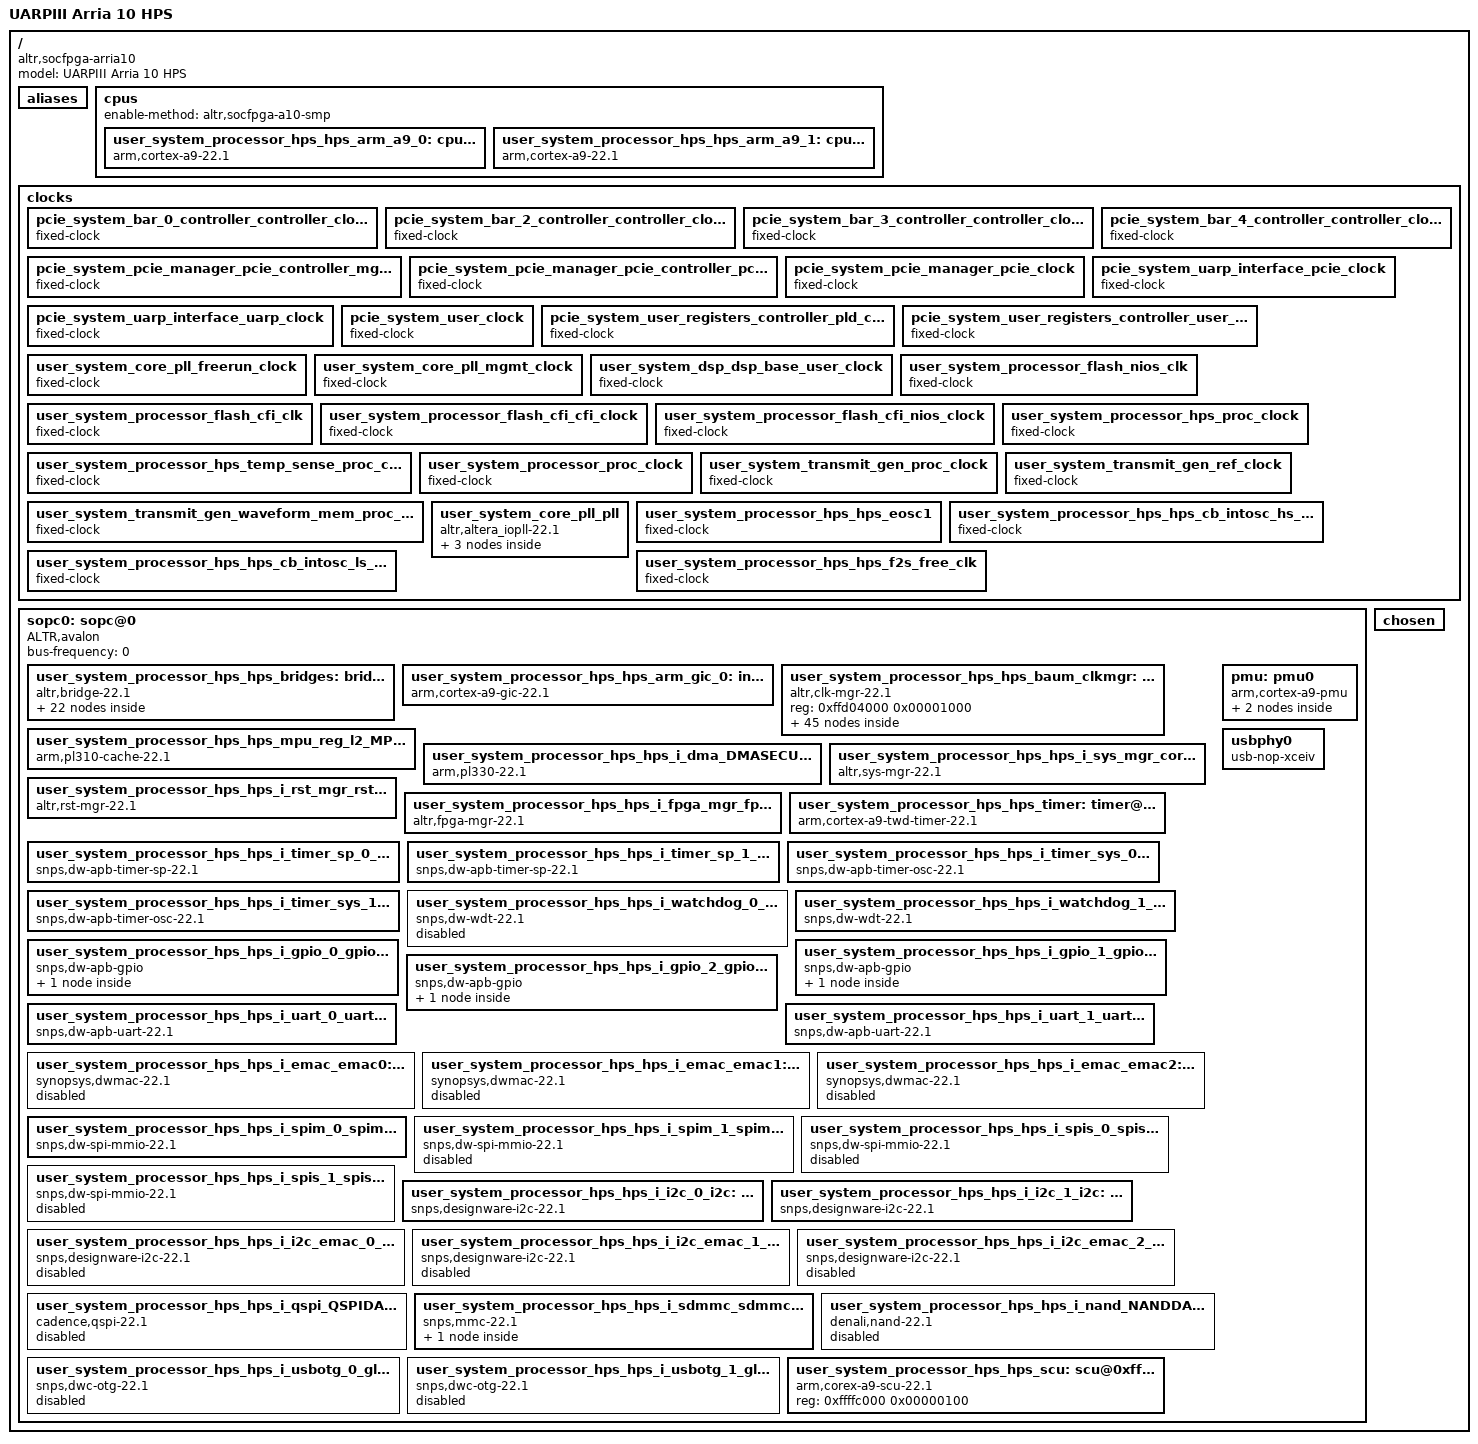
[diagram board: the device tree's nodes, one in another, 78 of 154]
/*
 * This devicetree is generated by sopc2dts version 20.1 [9b3346002ac555f36b80b1bc56dad1cb86298234] on Wed Jan 10 18:21:34 GMT 2024
 * Sopc2dts is written by Walter Goossens <waltergoossens@home.nl>
 * in cooperation with the nios2 community <nios2-dev@lists.rocketboards.org>
 */
/dts-v1/;

/ {
	model = "UARPIII Arria 10 HPS";	/* appended from boardinfo */
	compatible = "altr,socfpga-arria10", "altr,socfpga";	/* appended from boardinfo */
	#address-cells = <1>;
	#size-cells = <1>;

	aliases {
		serial0 = "/sopc@0/serial@0xffc02000";
		serial1 = "/sopc@0/serial@0xffc02100";
		watchdog0 = "/sopc@0/timer@0xffd00200";
		watchdog1 = "/sopc@0/timer@0xffd00300";
		bootargs = "console=ttyS0,115200";	/* appended from boardinfo */
	}; //end aliases

	cpus {
		#address-cells = <1>;
		#size-cells = <0>;
		enable-method = "altr,socfpga-a10-smp";	/* appended from boardinfo */

		user_system_processor_hps_hps_arm_a9_0: cpu@0x0 {
			device_type = "cpu";
			compatible = "arm,cortex-a9-22.1", "arm,cortex-a9";
			reg = <0x00000000>;
			next-level-cache = <&user_system_processor_hps_hps_mpu_reg_l2_MPUL2>;	/* appended from boardinfo */
		}; //end cpu@0x0 (user_system_processor_hps_hps_arm_a9_0)

		user_system_processor_hps_hps_arm_a9_1: cpu@0x1 {
			device_type = "cpu";
			compatible = "arm,cortex-a9-22.1", "arm,cortex-a9";
			reg = <0x00000001>;
			next-level-cache = <&user_system_processor_hps_hps_mpu_reg_l2_MPUL2>;	/* appended from boardinfo */
		}; //end cpu@0x1 (user_system_processor_hps_hps_arm_a9_1)
	}; //end cpus

	clocks {
		#address-cells = <1>;
		#size-cells = <1>;

		pcie_system_bar_0_controller_controller_clock: pcie_system_bar_0_controller_controller_clock {
			compatible = "fixed-clock";
			#clock-cells = <0>;
			clock-frequency = <250000000>;	/* 250.00 MHz */
			clock-output-names = "pcie_system_bar_0_controller_controller_clock-clk";
		}; //end pcie_system_bar_0_controller_controller_clock (pcie_system_bar_0_controller_controller_clock)

		pcie_system_bar_2_controller_controller_clock: pcie_system_bar_2_controller_controller_clock {
			compatible = "fixed-clock";
			#clock-cells = <0>;
			clock-frequency = <250000000>;	/* 250.00 MHz */
			clock-output-names = "pcie_system_bar_2_controller_controller_clock-clk";
		}; //end pcie_system_bar_2_controller_controller_clock (pcie_system_bar_2_controller_controller_clock)

		pcie_system_bar_3_controller_controller_clock: pcie_system_bar_3_controller_controller_clock {
			compatible = "fixed-clock";
			#clock-cells = <0>;
			clock-frequency = <250000000>;	/* 250.00 MHz */
			clock-output-names = "pcie_system_bar_3_controller_controller_clock-clk";
		}; //end pcie_system_bar_3_controller_controller_clock (pcie_system_bar_3_controller_controller_clock)

		pcie_system_bar_4_controller_controller_clock: pcie_system_bar_4_controller_controller_clock {
			compatible = "fixed-clock";
			#clock-cells = <0>;
			clock-frequency = <250000000>;	/* 250.00 MHz */
			clock-output-names = "pcie_system_bar_4_controller_controller_clock-clk";
		}; //end pcie_system_bar_4_controller_controller_clock (pcie_system_bar_4_controller_controller_clock)

		pcie_system_pcie_manager_pcie_controller_mgmt_clock: pcie_system_pcie_manager_pcie_controller_mgmt_clock {
			compatible = "fixed-clock";
			#clock-cells = <0>;
			clock-frequency = <0>;	/* 0.00 Hz */
			clock-output-names = "pcie_system_pcie_manager_pcie_controller_mgmt_clock-clk";
		}; //end pcie_system_pcie_manager_pcie_controller_mgmt_clock (pcie_system_pcie_manager_pcie_controller_mgmt_clock)

		pcie_system_pcie_manager_pcie_controller_pcie_clock: pcie_system_pcie_manager_pcie_controller_pcie_clock {
			compatible = "fixed-clock";
			#clock-cells = <0>;
			clock-frequency = <250000000>;	/* 250.00 MHz */
			clock-output-names = "pcie_system_pcie_manager_pcie_controller_pcie_clock-clk";
		}; //end pcie_system_pcie_manager_pcie_controller_pcie_clock (pcie_system_pcie_manager_pcie_controller_pcie_clock)

		pcie_system_pcie_manager_pcie_clock: pcie_system_pcie_manager_pcie_clock {
			compatible = "fixed-clock";
			#clock-cells = <0>;
			clock-frequency = <250000000>;	/* 250.00 MHz */
			clock-output-names = "pcie_system_pcie_manager_pcie_clock-clk";
		}; //end pcie_system_pcie_manager_pcie_clock (pcie_system_pcie_manager_pcie_clock)

		pcie_system_uarp_interface_pcie_clock: pcie_system_uarp_interface_pcie_clock {
			compatible = "fixed-clock";
			#clock-cells = <0>;
			clock-frequency = <250000000>;	/* 250.00 MHz */
			clock-output-names = "pcie_system_uarp_interface_pcie_clock-clk";
		}; //end pcie_system_uarp_interface_pcie_clock (pcie_system_uarp_interface_pcie_clock)

		pcie_system_uarp_interface_uarp_clock: pcie_system_uarp_interface_uarp_clock {
			compatible = "fixed-clock";
			#clock-cells = <0>;
			clock-frequency = <200000000>;	/* 200.00 MHz */
			clock-output-names = "pcie_system_uarp_interface_uarp_clock-clk";
		}; //end pcie_system_uarp_interface_uarp_clock (pcie_system_uarp_interface_uarp_clock)

		pcie_system_user_clock: pcie_system_user_clock {
			compatible = "fixed-clock";
			#clock-cells = <0>;
			clock-frequency = <200000000>;	/* 200.00 MHz */
			clock-output-names = "pcie_system_user_clock-clk";
		}; //end pcie_system_user_clock (pcie_system_user_clock)

		pcie_system_user_registers_controller_pld_clock: pcie_system_user_registers_controller_pld_clock {
			compatible = "fixed-clock";
			#clock-cells = <0>;
			clock-frequency = <250000000>;	/* 250.00 MHz */
			clock-output-names = "pcie_system_user_registers_controller_pld_clock-clk";
		}; //end pcie_system_user_registers_controller_pld_clock (pcie_system_user_registers_controller_pld_clock)

		pcie_system_user_registers_controller_user_clock: pcie_system_user_registers_controller_user_clock {
			compatible = "fixed-clock";
			#clock-cells = <0>;
			clock-frequency = <200000000>;	/* 200.00 MHz */
			clock-output-names = "pcie_system_user_registers_controller_user_clock-clk";
		}; //end pcie_system_user_registers_controller_user_clock (pcie_system_user_registers_controller_user_clock)

		user_system_core_pll_freerun_clock: user_system_core_pll_freerun_clock {
			compatible = "fixed-clock";
			#clock-cells = <0>;
			clock-frequency = <100000000>;	/* 100.00 MHz */
			clock-output-names = "user_system_core_pll_freerun_clock-clk";
		}; //end user_system_core_pll_freerun_clock (user_system_core_pll_freerun_clock)

		user_system_core_pll_mgmt_clock: user_system_core_pll_mgmt_clock {
			compatible = "fixed-clock";
			#clock-cells = <0>;
			clock-frequency = <100000000>;	/* 100.00 MHz */
			clock-output-names = "user_system_core_pll_mgmt_clock-clk";
		}; //end user_system_core_pll_mgmt_clock (user_system_core_pll_mgmt_clock)

		user_system_dsp_dsp_base_user_clock: user_system_dsp_dsp_base_user_clock {
			compatible = "fixed-clock";
			#clock-cells = <0>;
			clock-frequency = <200000000>;	/* 200.00 MHz */
			clock-output-names = "user_system_dsp_dsp_base_user_clock-clk";
		}; //end user_system_dsp_dsp_base_user_clock (user_system_dsp_dsp_base_user_clock)

		user_system_processor_flash_nios_clk: user_system_processor_flash_nios_clk {
			compatible = "fixed-clock";
			#clock-cells = <0>;
			clock-frequency = <200000000>;	/* 200.00 MHz */
			clock-output-names = "user_system_processor_flash_nios_clk-clk";
		}; //end user_system_processor_flash_nios_clk (user_system_processor_flash_nios_clk)

		user_system_processor_flash_cfi_clk: user_system_processor_flash_cfi_clk {
			compatible = "fixed-clock";
			#clock-cells = <0>;
			clock-frequency = <2500000>;	/* 2.50 MHz */
			clock-output-names = "user_system_processor_flash_cfi_clk-clk";
		}; //end user_system_processor_flash_cfi_clk (user_system_processor_flash_cfi_clk)

		user_system_processor_flash_cfi_cfi_clock: user_system_processor_flash_cfi_cfi_clock {
			compatible = "fixed-clock";
			#clock-cells = <0>;
			clock-frequency = <2500000>;	/* 2.50 MHz */
			clock-output-names = "user_system_processor_flash_cfi_cfi_clock-clk";
		}; //end user_system_processor_flash_cfi_cfi_clock (user_system_processor_flash_cfi_cfi_clock)

		user_system_processor_flash_cfi_nios_clock: user_system_processor_flash_cfi_nios_clock {
			compatible = "fixed-clock";
			#clock-cells = <0>;
			clock-frequency = <200000000>;	/* 200.00 MHz */
			clock-output-names = "user_system_processor_flash_cfi_nios_clock-clk";
		}; //end user_system_processor_flash_cfi_nios_clock (user_system_processor_flash_cfi_nios_clock)

		user_system_processor_hps_proc_clock: user_system_processor_hps_proc_clock {
			compatible = "fixed-clock";
			#clock-cells = <0>;
			clock-frequency = <200000000>;	/* 200.00 MHz */
			clock-output-names = "user_system_processor_hps_proc_clock-clk";
		}; //end user_system_processor_hps_proc_clock (user_system_processor_hps_proc_clock)

		user_system_processor_hps_temp_sense_proc_clock: user_system_processor_hps_temp_sense_proc_clock {
			compatible = "fixed-clock";
			#clock-cells = <0>;
			clock-frequency = <200000000>;	/* 200.00 MHz */
			clock-output-names = "user_system_processor_hps_temp_sense_proc_clock-clk";
		}; //end user_system_processor_hps_temp_sense_proc_clock (user_system_processor_hps_temp_sense_proc_clock)

		user_system_processor_proc_clock: user_system_processor_proc_clock {
			compatible = "fixed-clock";
			#clock-cells = <0>;
			clock-frequency = <200000000>;	/* 200.00 MHz */
			clock-output-names = "user_system_processor_proc_clock-clk";
		}; //end user_system_processor_proc_clock (user_system_processor_proc_clock)

		user_system_transmit_gen_proc_clock: user_system_transmit_gen_proc_clock {
			compatible = "fixed-clock";
			#clock-cells = <0>;
			clock-frequency = <200000000>;	/* 200.00 MHz */
			clock-output-names = "user_system_transmit_gen_proc_clock-clk";
		}; //end user_system_transmit_gen_proc_clock (user_system_transmit_gen_proc_clock)

		user_system_transmit_gen_ref_clock: user_system_transmit_gen_ref_clock {
			compatible = "fixed-clock";
			#clock-cells = <0>;
			clock-frequency = <20000000>;	/* 20.00 MHz */
			clock-output-names = "user_system_transmit_gen_ref_clock-clk";
		}; //end user_system_transmit_gen_ref_clock (user_system_transmit_gen_ref_clock)

		user_system_transmit_gen_waveform_mem_proc_clock: user_system_transmit_gen_waveform_mem_proc_clock {
			compatible = "fixed-clock";
			#clock-cells = <0>;
			clock-frequency = <200000000>;	/* 200.00 MHz */
			clock-output-names = "user_system_transmit_gen_waveform_mem_proc_clock-clk";
		}; //end user_system_transmit_gen_waveform_mem_proc_clock (user_system_transmit_gen_waveform_mem_proc_clock)

		user_system_core_pll_pll: user_system_core_pll_pll {
			compatible = "altr,altera_iopll-22.1";
			#clock-cells = <1>;

			user_system_core_pll_pll_outclk0: user_system_core_pll_pll_outclk0 {
				compatible = "fixed-clock";
				#clock-cells = <0>;
				clock-frequency = <20000000>;	/* 20.00 MHz */
				clock-output-names = "user_system_core_pll_pll-outclk0";
			}; //end user_system_core_pll_pll_outclk0 (user_system_core_pll_pll_outclk0)

			user_system_core_pll_pll_outclk1: user_system_core_pll_pll_outclk1 {
				compatible = "fixed-clock";
				#clock-cells = <0>;
				clock-frequency = <120000000>;	/* 120.00 MHz */
				clock-output-names = "user_system_core_pll_pll-outclk1";
			}; //end user_system_core_pll_pll_outclk1 (user_system_core_pll_pll_outclk1)

			user_system_core_pll_pll_outclk2: user_system_core_pll_pll_outclk2 {
				compatible = "fixed-clock";
				#clock-cells = <0>;
				clock-frequency = <240000000>;	/* 240.00 MHz */
				clock-output-names = "user_system_core_pll_pll-outclk2";
			}; //end user_system_core_pll_pll_outclk2 (user_system_core_pll_pll_outclk2)
		}; //end user_system_core_pll_pll (user_system_core_pll_pll)

		user_system_processor_hps_hps_eosc1: user_system_processor_hps_hps_eosc1 {
			compatible = "fixed-clock";
			#clock-cells = <0>;
			clock-frequency = <25000000>;	/* 25.00 MHz */
			clock-output-names = "user_system_processor_hps_hps_eosc1-clk";
		}; //end user_system_processor_hps_hps_eosc1 (user_system_processor_hps_hps_eosc1)

		user_system_processor_hps_hps_cb_intosc_hs_div2_clk: user_system_processor_hps_hps_cb_intosc_hs_div2_clk {
			compatible = "fixed-clock";
			#clock-cells = <0>;
			clock-frequency = <0>;	/* 0.00 Hz */
			clock-output-names = "user_system_processor_hps_hps_cb_intosc_hs_div2_clk-clk";
		}; //end user_system_processor_hps_hps_cb_intosc_hs_div2_clk (user_system_processor_hps_hps_cb_intosc_hs_div2_clk)

		user_system_processor_hps_hps_cb_intosc_ls_clk: user_system_processor_hps_hps_cb_intosc_ls_clk {
			compatible = "fixed-clock";
			#clock-cells = <0>;
			clock-frequency = <60000000>;	/* 60.00 MHz */
			clock-output-names = "user_system_processor_hps_hps_cb_intosc_ls_clk-clk";
		}; //end user_system_processor_hps_hps_cb_intosc_ls_clk (user_system_processor_hps_hps_cb_intosc_ls_clk)

		user_system_processor_hps_hps_f2s_free_clk: user_system_processor_hps_hps_f2s_free_clk {
			compatible = "fixed-clock";
			#clock-cells = <0>;
			clock-frequency = <200000000>;	/* 200.00 MHz */
			clock-output-names = "user_system_processor_hps_hps_f2s_free_clk-clk";
		}; //end user_system_processor_hps_hps_f2s_free_clk (user_system_processor_hps_hps_f2s_free_clk)
	}; //end clocks

	sopc0: sopc@0 {
		device_type = "soc";
		ranges;
		#address-cells = <1>;
		#size-cells = <1>;
		compatible = "ALTR,avalon", "simple-bus";
		bus-frequency = <0>;

		user_system_processor_hps_hps_bridges: bridge@0xc0000000 {
			compatible = "altr,bridge-22.1", "simple-bus";
			reg = <0xc0000000 0x20000000>,
				<0xff200000 0x00200000>;
			reg-names = "axi_h2f", "axi_h2f_lw";
			clocks = <&user_system_processor_hps_proc_clock &user_system_processor_hps_proc_clock>;
			clock-names = "h2f_axi_clock", "h2f_lw_axi_clock";
			#address-cells = <2>;
			#size-cells = <1>;
			ranges = <0x00000000 0x2e000000 0xee000000 0x00002000>,
				<0x00000000 0x2f000000 0xef000000 0x00010000>,
				<0x00000000 0x30000000 0xf0000000 0x00000040>,
				<0x00000000 0x34000000 0xf4000000 0x04000000>,
				<0x00000001 0x001c0000 0xff3c0000 0x00000008>,
				<0x00000001 0x001c4000 0xff3c4000 0x00000020>,
				<0x00000001 0x001c4400 0xff3c4400 0x00000020>,
				<0x00000001 0x001c4800 0xff3c4800 0x00000020>,
				<0x00000001 0x001c8000 0xff3c8000 0x00000004>,
				<0x00000001 0x00010000 0xff210000 0x00000020>,
				<0x00000001 0x00000000 0xff200000 0x00000020>,
				<0x00000001 0x00008000 0xff208000 0x00000010>,
				<0x00000001 0x00004000 0xff204000 0x00000040>,
				<0x00000001 0x00114000 0xff314000 0x00000010>,
				<0x00000001 0x00104010 0xff304010 0x00000010>,
				<0x00000001 0x00104000 0xff304000 0x00000010>,
				<0x00000001 0x00108000 0xff308000 0x00000400>,
				<0x00000001 0x0010c000 0xff30c000 0x00001000>,
				<0x00000001 0x00140000 0xff340000 0x00040000>,
				<0x00000001 0x00100000 0xff300000 0x00000010>,
				<0x00000001 0x0012c000 0xff32c000 0x00000800>,
				<0x00000001 0x0012c800 0xff32c800 0x00000010>,
				<0x00000001 0x0012d000 0xff32d000 0x00000004>;

			user_system_processor_pcie_read_mem: unknown@0x02e000000 {
				compatible = "unknown,unknown-1.0";
				reg = <0x00000000 0x2e000000 0x00002000>;
				clocks = <&user_system_processor_proc_clock>;
			}; //end unknown@0x02e000000 (user_system_processor_pcie_read_mem)

			user_system_processor_pcie_write_width: unknown@0x02f000000 {
				compatible = "unknown,unknown-1.0";
				reg = <0x00000000 0x2f000000 0x00010000>;
				clocks = <&user_system_processor_proc_clock>;
			}; //end unknown@0x02f000000 (user_system_processor_pcie_write_width)

			user_system_processor_flash_cfi_mac: quadspi@0x030000000 {
				compatible = "altr,quadspi-22.1", "altr,quadspi-2.0";
				reg = <0x00000000 0x30000000 0x00000040>,
					<0x00000000 0x34000000 0x04000000>;
				reg-names = "avl_csr", "avl_mem";
				clocks = <&user_system_processor_flash_cfi_cfi_clock>;
			}; //end quadspi@0x030000000 (user_system_processor_flash_cfi_mac)

			user_system_processor_hps_hps_sysid: sysid@0x1001c0000 {
				compatible = "altr,sysid-22.1", "altr,sysid-1.0";
				reg = <0x00000001 0x001c0000 0x00000008>;
				clocks = <&user_system_processor_hps_proc_clock>;
				id = <1887048173>;	/* embeddedsw.dts.params.id type NUMBER */
				timestamp = <1704296836>;	/* embeddedsw.dts.params.timestamp type NUMBER */
			}; //end sysid@0x1001c0000 (user_system_processor_hps_hps_sysid)

			user_system_processor_hps_crc16_processor: unknown@0x1001c4000 {
				compatible = "unknown,unknown-1.0";
				reg = <0x00000001 0x001c4000 0x00000020>;
				clocks = <&user_system_processor_hps_proc_clock>;
			}; //end unknown@0x1001c4000 (user_system_processor_hps_crc16_processor)

			user_system_processor_hps_crc32_processor: unknown@0x1001c4400 {
				compatible = "unknown,unknown-1.0";
				reg = <0x00000001 0x001c4400 0x00000020>;
				clocks = <&user_system_processor_hps_proc_clock>;
			}; //end unknown@0x1001c4400 (user_system_processor_hps_crc32_processor)

			user_system_processor_hps_mosys_ecc19: unknown@0x1001c4800 {
				compatible = "unknown,unknown-1.0";
				reg = <0x00000001 0x001c4800 0x00000020>;
				clocks = <&user_system_processor_hps_proc_clock>;
			}; //end unknown@0x1001c4800 (user_system_processor_hps_mosys_ecc19)

			user_system_processor_hps_temp_sense_tsd_controller: unknown@0x1001c8000 {
				compatible = "unknown,unknown-1.0";
				reg = <0x00000001 0x001c8000 0x00000004>;
				clocks = <&user_system_processor_hps_temp_sense_proc_clock>;
			}; //end unknown@0x1001c8000 (user_system_processor_hps_temp_sense_tsd_controller)

			user_system_global_csr: unknown@0x100010000 {
				compatible = "unknown,unknown-1.0";
				reg = <0x00000001 0x00010000 0x00000020>;
				interrupt-parent = <&user_system_processor_hps_hps_arm_gic_0>;
				interrupts = <0 24 4>;
			}; //end unknown@0x100010000 (user_system_global_csr)

			user_system_dsp_dsp_base_dma_read_controller: unknown@0x100000000 {
				compatible = "unknown,unknown-1.0";
				reg = <0x00000001 0x00000000 0x00000020>;
				interrupt-parent = <&user_system_processor_hps_hps_arm_gic_0>;
				interrupts = <0 23 4>;
				clocks = <&user_system_dsp_dsp_base_user_clock>;
			}; //end unknown@0x100000000 (user_system_dsp_dsp_base_dma_read_controller)

			user_system_dsp_sample_processor: unknown@0x100008000 {
				compatible = "unknown,unknown-1.0";
				reg = <0x00000001 0x00008000 0x00000010>;
				interrupt-parent = <&user_system_processor_hps_hps_arm_gic_0>;
				interrupts = <0 25 4>;
				interrupt-controller;
				#interrupt-cells = <1>;
			}; //end unknown@0x100008000 (user_system_dsp_sample_processor)

			user_system_dsp_dsp_base_processing_csr_null: unknown@0x100004000 {
				compatible = "unknown,unknown-1.0";
				reg = <0x00000001 0x00004000 0x00000040>;
				clocks = <&user_system_dsp_dsp_base_user_clock>;
			}; //end unknown@0x100004000 (user_system_dsp_dsp_base_processing_csr_null)

			user_system_processor_modbus: unknown@0x100114000 {
				compatible = "unknown,unknown-1.0";
				reg = <0x00000001 0x00114000 0x00000010>;
				interrupt-parent = <&user_system_processor_hps_hps_arm_gic_0>;
				interrupts = <0 51 4>;
				clocks = <&user_system_processor_proc_clock>;
			}; //end unknown@0x100114000 (user_system_processor_modbus)

			user_system_processor_high_queue: unknown@0x100104010 {
				compatible = "unknown,unknown-1.0";
				reg = <0x00000001 0x00104010 0x00000010>;
				clocks = <&user_system_processor_proc_clock>;
			}; //end unknown@0x100104010 (user_system_processor_high_queue)

			user_system_processor_low_queue: unknown@0x100104000 {
				compatible = "unknown,unknown-1.0";
				reg = <0x00000001 0x00104000 0x00000010>;
				clocks = <&user_system_processor_proc_clock>;
			}; //end unknown@0x100104000 (user_system_processor_low_queue)

			user_system_processor_tlp_dma: unknown@0x100108000 {
				compatible = "unknown,unknown-1.0";
				reg = <0x00000001 0x00108000 0x00000400>;
				clocks = <&user_system_processor_proc_clock>;
			}; //end unknown@0x100108000 (user_system_processor_tlp_dma)

			user_system_processor_pcie_config_mem: unknown@0x10010c000 {
				compatible = "unknown,unknown-1.0";
				reg = <0x00000001 0x0010c000 0x00001000>;
				clocks = <&user_system_processor_proc_clock>;
			}; //end unknown@0x10010c000 (user_system_processor_pcie_config_mem)

			user_system_processor_sample_map: unknown@0x100140000 {
				compatible = "unknown,unknown-1.0";
				reg = <0x00000001 0x00140000 0x00040000>;
				clocks = <&user_system_processor_proc_clock>;
			}; //end unknown@0x100140000 (user_system_processor_sample_map)

			user_system_processor_flash_cfi_watchdog_fpga: gpio@0x100100000 {
				compatible = "altr,pio-22.1", "altr,pio-1.0";
				reg = <0x00000001 0x00100000 0x00000010>;
				clocks = <&user_system_processor_flash_cfi_nios_clock>;
				altr,gpio-bank-width = <1>;	/* embeddedsw.dts.params.altr,gpio-bank-width type NUMBER */
				resetvalue = <0>;	/* embeddedsw.dts.params.resetvalue type NUMBER */
				#gpio-cells = <2>;
				gpio-controller;
			}; //end gpio@0x100100000 (user_system_processor_flash_cfi_watchdog_fpga)

			user_system_core_pll_pll_reconfig: unknown@0x10012c000 {
				compatible = "unknown,unknown-22.1";
				reg = <0x00000001 0x0012c000 0x00000800>;
				clocks = <&user_system_core_pll_mgmt_clock>;
			}; //end unknown@0x10012c000 (user_system_core_pll_pll_reconfig)

			user_system_core_pll_pll_reconfig_pio: gpio@0x10012c800 {
				compatible = "altr,pio-1.0", "altr,pio-1.0";
				reg = <0x00000001 0x0012c800 0x00000010>;
				clocks = <&user_system_core_pll_mgmt_clock>;
				altr,gpio-bank-width = <2>;	/* embeddedsw.dts.params.altr,gpio-bank-width type NUMBER */
				resetvalue = <0>;	/* embeddedsw.dts.params.resetvalue type NUMBER */
				#gpio-cells = <2>;
				gpio-controller;
			}; //end gpio@0x10012c800 (user_system_core_pll_pll_reconfig_pio)

			user_system_core_pll_trig_clk_sel: unknown@0x10012d000 {
				compatible = "unknown,unknown-1.0";
				reg = <0x00000001 0x0012d000 0x00000004>;
				clocks = <&user_system_core_pll_mgmt_clock>;
			}; //end unknown@0x10012d000 (user_system_core_pll_trig_clk_sel)
		}; //end bridge@0xc0000000 (user_system_processor_hps_hps_bridges)

		user_system_processor_hps_hps_arm_gic_0: intc@0xffffd000 {
			compatible = "arm,cortex-a9-gic-22.1", "arm,cortex-a9-gic";
			reg = <0xffffd000 0x00001000>,
				<0xffffc100 0x00000100>;
			reg-names = "axi_slave0", "axi_slave1";
			interrupt-controller;
			#interrupt-cells = <3>;
		}; //end intc@0xffffd000 (user_system_processor_hps_hps_arm_gic_0)

		user_system_processor_hps_hps_baum_clkmgr: clkmgr@0xffd04000 {
			compatible = "altr,clk-mgr-22.1", "altr,clk-mgr";
			reg = <0xffd04000 0x00001000>;
			clock-names = "eosc1", "cb_intosc_hs_div2_clk", "cb_intosc_ls_clk", "f2s_free_clk";

			clocks {
				#size-cells = <0>;
				#address-cells = <1>;

				main_pll: main_pll {
					compatible = "altr,socfpga-a10-pll-clock";
					reg = <0x00000040>;
					clocks = <&user_system_processor_hps_hps_eosc1 &user_system_processor_hps_hps_cb_intosc_ls_clk &user_system_processor_hps_hps_f2s_free_clk>;
					clock-names = "user_system_processor_hps_hps_eosc1", "user_system_processor_hps_hps_cb_intosc_ls_clk", "user_system_processor_hps_hps_f2s_free_clk";
					#clock-cells = <0>;
					#address-cells = <1>;
					#size-cells = <0>;

					main_mpu_base_clk: main_mpu_base_clk {
						compatible = "altr,socfpga-a10-perip-clk";
						clocks = <&main_pll>;
						#clock-cells = <0>;
						div-reg = <0x00000140 0x00000000 0x0000000b>;
					}; //end main_mpu_base_clk (main_mpu_base_clk)

					main_noc_base_clk: main_noc_base_clk {
						compatible = "altr,socfpga-a10-perip-clk";
						clocks = <&main_pll>;
						#clock-cells = <0>;
						div-reg = <0x00000144 0x00000000 0x0000000b>;
					}; //end main_noc_base_clk (main_noc_base_clk)

					main_emaca_clk: main_emaca_clk {
						compatible = "altr,socfpga-a10-perip-clk";
						reg = <0x00000068>;
						clocks = <&main_pll>;
						#clock-cells = <0>;
					}; //end main_emaca_clk (main_emaca_clk)

					main_emacb_clk: main_emacb_clk {
						compatible = "altr,socfpga-a10-perip-clk";
						reg = <0x0000006c>;
						clocks = <&main_pll>;
						#clock-cells = <0>;
					}; //end main_emacb_clk (main_emacb_clk)

					main_emac_ptp_clk: main_emac_ptp_clk {
						compatible = "altr,socfpga-a10-perip-clk";
						reg = <0x00000070>;
						clocks = <&main_pll>;
						#clock-cells = <0>;
					}; //end main_emac_ptp_clk (main_emac_ptp_clk)

					main_gpio_db_clk: main_gpio_db_clk {
						compatible = "altr,socfpga-a10-perip-clk";
						reg = <0x00000074>;
						clocks = <&main_pll>;
						#clock-cells = <0>;
					}; //end main_gpio_db_clk (main_gpio_db_clk)

					main_sdmmc_clk: main_sdmmc_clk {
						compatible = "altr,socfpga-a10-perip-clk";
						reg = <0x00000078>;
						clocks = <&main_pll>;
						#clock-cells = <0>;
					}; //end main_sdmmc_clk (main_sdmmc_clk)

					main_s2f_usr0_clk: main_s2f_usr0_clk {
						compatible = "altr,socfpga-a10-perip-clk";
						reg = <0x0000007c>;
						clocks = <&main_pll>;
						#clock-cells = <0>;
					}; //end main_s2f_usr0_clk (main_s2f_usr0_clk)

					main_s2f_usr1_clk: main_s2f_usr1_clk {
						compatible = "altr,socfpga-a10-perip-clk";
						reg = <0x00000080>;
						clocks = <&main_pll>;
						#clock-cells = <0>;
					}; //end main_s2f_usr1_clk (main_s2f_usr1_clk)

					main_hmc_pll_ref_clk: main_hmc_pll_ref_clk {
						compatible = "altr,socfpga-a10-perip-clk";
						reg = <0x00000084>;
						clocks = <&main_pll>;
						#clock-cells = <0>;
					}; //end main_hmc_pll_ref_clk (main_hmc_pll_ref_clk)

					main_periph_ref_clk: main_periph_ref_clk {
						compatible = "altr,socfpga-a10-perip-clk";
						reg = <0x0000009c>;
						clocks = <&main_pll>;
						#clock-cells = <0>;
					}; //end main_periph_ref_clk (main_periph_ref_clk)
				}; //end main_pll (main_pll)

				periph_pll: periph_pll {
					compatible = "altr,socfpga-a10-pll-clock";
					reg = <0x000000c0>;
					clocks = <&user_system_processor_hps_hps_eosc1 &user_system_processor_hps_hps_cb_intosc_ls_clk &user_system_processor_hps_hps_f2s_free_clk &main_periph_ref_clk>;
					clock-names = "user_system_processor_hps_hps_eosc1", "user_system_processor_hps_hps_cb_intosc_ls_clk", "user_system_processor_hps_hps_f2s_free_clk", "main_periph_ref_clk";
					#clock-cells = <0>;
					#address-cells = <1>;
					#size-cells = <0>;

					peri_mpu_base_clk: peri_mpu_base_clk {
						compatible = "altr,socfpga-a10-perip-clk";
						clocks = <&periph_pll>;
						#clock-cells = <0>;
						div-reg = <0x00000140 0x00000010 0x0000000b>;
					}; //end peri_mpu_base_clk (peri_mpu_base_clk)

					peri_noc_base_clk: peri_noc_base_clk {
						compatible = "altr,socfpga-a10-perip-clk";
						clocks = <&periph_pll>;
						#clock-cells = <0>;
						div-reg = <0x00000144 0x00000010 0x0000000b>;
					}; //end peri_noc_base_clk (peri_noc_base_clk)

					peri_emaca_clk: peri_emaca_clk {
						compatible = "altr,socfpga-a10-perip-clk";
						reg = <0x000000e8>;
						clocks = <&periph_pll>;
						#clock-cells = <0>;
					}; //end peri_emaca_clk (peri_emaca_clk)

					peri_emacb_clk: peri_emacb_clk {
						compatible = "altr,socfpga-a10-perip-clk";
						reg = <0x000000ec>;
						clocks = <&periph_pll>;
						#clock-cells = <0>;
					}; //end peri_emacb_clk (peri_emacb_clk)

					peri_emac_ptp_clk: peri_emac_ptp_clk {
						compatible = "altr,socfpga-a10-perip-clk";
						reg = <0x000000f0>;
						clocks = <&periph_pll>;
						#clock-cells = <0>;
					}; //end peri_emac_ptp_clk (peri_emac_ptp_clk)

					peri_gpio_db_clk: peri_gpio_db_clk {
						compatible = "altr,socfpga-a10-perip-clk";
						reg = <0x000000f4>;
						clocks = <&periph_pll>;
						#clock-cells = <0>;
					}; //end peri_gpio_db_clk (peri_gpio_db_clk)

					peri_sdmmc_clk: peri_sdmmc_clk {
						compatible = "altr,socfpga-a10-perip-clk";
						reg = <0x000000f8>;
						clocks = <&periph_pll>;
						#clock-cells = <0>;
					}; //end peri_sdmmc_clk (peri_sdmmc_clk)

					peri_s2f_usr0_clk: peri_s2f_usr0_clk {
						compatible = "altr,socfpga-a10-perip-clk";
						reg = <0x000000fc>;
						clocks = <&periph_pll>;
						#clock-cells = <0>;
					}; //end peri_s2f_usr0_clk (peri_s2f_usr0_clk)

					peri_s2f_usr1_clk: peri_s2f_usr1_clk {
						compatible = "altr,socfpga-a10-perip-clk";
						reg = <0x00000100>;
						clocks = <&periph_pll>;
						#clock-cells = <0>;
					}; //end peri_s2f_usr1_clk (peri_s2f_usr1_clk)

					peri_hmc_pll_ref_clk: peri_hmc_pll_ref_clk {
						compatible = "altr,socfpga-a10-perip-clk";
						reg = <0x00000104>;
						clocks = <&periph_pll>;
						#clock-cells = <0>;
					}; //end peri_hmc_pll_ref_clk (peri_hmc_pll_ref_clk)
				}; //end periph_pll (periph_pll)

				mpu_periph_clk: mpu_periph_clk {
					compatible = "altr,socfpga-a10-gate-clk";
					clocks = <&mpu_free_clk>;
					#clock-cells = <0>;
					clk-gate = <0x00000048 0x00000000>;
					fixed-divider = <4>;
				}; //end mpu_periph_clk (mpu_periph_clk)

				l4_main_clk: l4_main_clk {
					compatible = "altr,socfpga-a10-gate-clk";
					clocks = <&noc_free_clk>;
					#clock-cells = <0>;
					clk-gate = <0x00000048 0x00000001>;
					div-reg = <0x000000a8 0x00000000 0x00000002>;
				}; //end l4_main_clk (l4_main_clk)

				l4_mp_clk: l4_mp_clk {
					compatible = "altr,socfpga-a10-gate-clk";
					clocks = <&noc_free_clk>;
					#clock-cells = <0>;
					clk-gate = <0x00000048 0x00000002>;
					div-reg = <0x000000a8 0x00000008 0x00000002>;
				}; //end l4_mp_clk (l4_mp_clk)

				l4_sp_clk: l4_sp_clk {
					compatible = "altr,socfpga-a10-gate-clk";
					clocks = <&noc_free_clk>;
					#clock-cells = <0>;
					clk-gate = <0x00000048 0x00000003>;
					div-reg = <0x000000a8 0x00000010 0x00000002>;
				}; //end l4_sp_clk (l4_sp_clk)

				emac0_clk: emac0_clk {
					compatible = "altr,socfpga-a10-gate-clk";
					#clock-cells = <0>;
					clk-gate = <0x000000c8 0x00000000>;
				}; //end emac0_clk (emac0_clk)

				emac1_clk: emac1_clk {
					compatible = "altr,socfpga-a10-gate-clk";
					#clock-cells = <0>;
					clk-gate = <0x000000c8 0x00000001>;
				}; //end emac1_clk (emac1_clk)

				emac2_clk: emac2_clk {
					compatible = "altr,socfpga-a10-gate-clk";
					#clock-cells = <0>;
					clk-gate = <0x000000c8 0x00000002>;
				}; //end emac2_clk (emac2_clk)

				emac_ptp_clk: emac_ptp_clk {
					compatible = "altr,socfpga-a10-gate-clk";
					#clock-cells = <0>;
					clk-gate = <0x000000c8 0x00000003>;
				}; //end emac_ptp_clk (emac_ptp_clk)

				gpio_db_clk: gpio_db_clk {
					compatible = "altr,socfpga-a10-gate-clk";
					#clock-cells = <0>;
					clk-gate = <0x000000c8 0x00000004>;
				}; //end gpio_db_clk (gpio_db_clk)

				sdmmc_clk: sdmmc_clk {
					compatible = "altr,socfpga-a10-gate-clk";
					clocks = <&sdmmc_free_clk>;
					#clock-cells = <0>;
					clk-gate = <0x000000c8 0x00000005>;
					clk-phase = <0 135>;	/* appended from boardinfo */
				}; //end sdmmc_clk (sdmmc_clk)

				s2f_user1_clk: s2f_user1_clk {
					compatible = "altr,socfpga-a10-gate-clk";
					clocks = <&peri_s2f_usr1_clk>;
					#clock-cells = <0>;
					clk-gate = <0x000000c8 0x00000006>;
				}; //end s2f_user1_clk (s2f_user1_clk)

				reserved: reserved {
					compatible = "altr,socfpga-a10-gate-clk";
					#clock-cells = <0>;
					clk-gate = <0x000000c8 0x00000007>;
				}; //end reserved (reserved)

				usb_clk: usb_clk {
					compatible = "altr,socfpga-a10-gate-clk";
					clocks = <&l4_mp_clk>;
					#clock-cells = <0>;
					clk-gate = <0x000000c8 0x00000008>;
				}; //end usb_clk (usb_clk)

				spi_m_clk: spi_m_clk {
					compatible = "altr,socfpga-a10-gate-clk";
					clocks = <&l4_main_clk>;
					#clock-cells = <0>;
					clk-gate = <0x000000c8 0x00000009>;
				}; //end spi_m_clk (spi_m_clk)

				nand_clk: nand_clk {
					compatible = "altr,socfpga-a10-gate-clk";
					clocks = <&l4_mp_clk>;
					#clock-cells = <0>;
					clk-gate = <0x000000c8 0x0000000a>;
				}; //end nand_clk (nand_clk)

				qspi_clk: qspi_clk {
					compatible = "altr,socfpga-a10-gate-clk";
					clocks = <&l4_main_clk>;
					#clock-cells = <0>;
					clk-gate = <0x000000c8 0x0000000b>;
				}; //end qspi_clk (qspi_clk)

				mpu_free_clk: mpu_free_clk {
					compatible = "altr,socfpga-a10-perip-clk";
					clocks = <&main_mpu_base_clk &peri_mpu_base_clk &user_system_processor_hps_hps_eosc1 &user_system_processor_hps_hps_cb_intosc_hs_div2_clk &user_system_processor_hps_hps_f2s_free_clk>;
					clock-names = "main_mpu_base_clk", "peri_mpu_base_clk", "user_system_processor_hps_hps_eosc1", "user_system_processor_hps_hps_cb_intosc_hs_div2_clk", "user_system_processor_hps_hps_f2s_free_clk";
					#clock-cells = <0>;
					reg = <0x00000060>;
				}; //end mpu_free_clk (mpu_free_clk)

				noc_free_clk: noc_free_clk {
					compatible = "altr,socfpga-a10-perip-clk";
					clocks = <&main_noc_base_clk &peri_noc_base_clk &user_system_processor_hps_hps_eosc1 &user_system_processor_hps_hps_cb_intosc_hs_div2_clk &user_system_processor_hps_hps_f2s_free_clk>;
					clock-names = "main_noc_base_clk", "peri_noc_base_clk", "user_system_processor_hps_hps_eosc1", "user_system_processor_hps_hps_cb_intosc_hs_div2_clk", "user_system_processor_hps_hps_f2s_free_clk";
					#clock-cells = <0>;
					reg = <0x00000064>;
				}; //end noc_free_clk (noc_free_clk)

				s2f_usr1_clk: s2f_usr1_clk {
					compatible = "altr,socfpga-a10-perip-clk";
					clocks = <&main_s2f_usr1_clk &peri_s2f_usr1_clk &user_system_processor_hps_hps_eosc1 &user_system_processor_hps_hps_cb_intosc_hs_div2_clk &user_system_processor_hps_hps_f2s_free_clk>;
					clock-names = "main_s2f_usr1_clk", "peri_s2f_usr1_clk", "user_system_processor_hps_hps_eosc1", "user_system_processor_hps_hps_cb_intosc_hs_div2_clk", "user_system_processor_hps_hps_f2s_free_clk";
					#clock-cells = <0>;
					reg = <0x00000104>;
				}; //end s2f_usr1_clk (s2f_usr1_clk)

				sdmmc_free_clk: sdmmc_free_clk {
					compatible = "altr,socfpga-a10-perip-clk";
					clocks = <&main_sdmmc_clk &peri_sdmmc_clk &user_system_processor_hps_hps_eosc1 &user_system_processor_hps_hps_cb_intosc_hs_div2_clk &user_system_processor_hps_hps_f2s_free_clk>;
					clock-names = "main_sdmmc_clk", "peri_sdmmc_clk", "user_system_processor_hps_hps_eosc1", "user_system_processor_hps_hps_cb_intosc_hs_div2_clk", "user_system_processor_hps_hps_f2s_free_clk";
					#clock-cells = <0>;
					reg = <0x000000f8>;
					fixed-divider = <4>;
				}; //end sdmmc_free_clk (sdmmc_free_clk)

				l4_sys_free_clk: l4_sys_free_clk {
					compatible = "altr,socfpga-a10-perip-clk";
					clocks = <&noc_free_clk>;
					#clock-cells = <0>;
					fixed-divider = <4>;
				}; //end l4_sys_free_clk (l4_sys_free_clk)
			}; //end clock_tree
		}; //end clkmgr@0xffd04000 (user_system_processor_hps_hps_baum_clkmgr)

		user_system_processor_hps_hps_mpu_reg_l2_MPUL2: L2-cache@0xfffff000 {
			compatible = "arm,pl310-cache-22.1", "arm,pl310-cache";
			reg = <0xfffff000 0x00001000>;
			interrupt-parent = <&user_system_processor_hps_hps_arm_gic_0>;
			interrupts = <0 18 4>;
			cache-level = <2>;	/* embeddedsw.dts.params.cache-level type NUMBER */
			cache-unified;	/* appended from boardinfo */
			arm,tag-latency = <1 1 1>;	/* appended from boardinfo */
			arm,data-latency = <2 1 1>;	/* appended from boardinfo */
		}; //end L2-cache@0xfffff000 (user_system_processor_hps_hps_mpu_reg_l2_MPUL2)

		user_system_processor_hps_hps_i_dma_DMASECURE: dma@0xffda1000 {
			compatible = "arm,pl330-22.1", "arm,pl330", "arm,primecell";
			reg = <0xffda1000 0x00001000>;
			interrupt-parent = <&user_system_processor_hps_hps_arm_gic_0>;
			interrupts = <0 83 4>;
			clocks = <&l4_main_clk>;
			#dma-cells = <1>;	/* embeddedsw.dts.params.#dma-cells type NUMBER */
			#dma-channels = <8>;	/* embeddedsw.dts.params.#dma-channels type NUMBER */
			#dma-requests = <32>;	/* embeddedsw.dts.params.#dma-requests type NUMBER */
			clock-names = "apb_pclk";	/* embeddedsw.dts.params.clock-names type STRING */
			copy-align = <3>;	/* embeddedsw.dts.params.copy-align type NUMBER */
			nr-irqs = <9>;	/* embeddedsw.dts.params.nr-irqs type NUMBER */
			nr-valid-peri = <9>;	/* embeddedsw.dts.params.nr-valid-peri type NUMBER */
		}; //end dma@0xffda1000 (user_system_processor_hps_hps_i_dma_DMASECURE)

		user_system_processor_hps_hps_i_sys_mgr_core: sysmgr@0xffd06000 {
			compatible = "altr,sys-mgr-22.1", "altr,sys-mgr", "syscon";
			reg = <0xffd06000 0x00000400>;
			cpu1-start-addr = <4291846704>;	/* embeddedsw.dts.params.cpu1-start-addr type NUMBER */
		}; //end sysmgr@0xffd06000 (user_system_processor_hps_hps_i_sys_mgr_core)

		user_system_processor_hps_hps_i_rst_mgr_rstmgr: rstmgr@0xffd05000 {
			compatible = "altr,rst-mgr-22.1", "altr,rst-mgr", "syscon";
			reg = <0xffd05000 0x00000100>;
			#reset-cells = <1>;	/* embeddedsw.dts.params.#reset-cells type NUMBER */
			altr,modrst-offset = <32>;	/* embeddedsw.dts.params.altr,modrst-offset type NUMBER */
		}; //end rstmgr@0xffd05000 (user_system_processor_hps_hps_i_rst_mgr_rstmgr)

		user_system_processor_hps_hps_i_fpga_mgr_fpgamgrregs: fpgamgr@0xffd03000 {
			compatible = "altr,fpga-mgr-22.1", "altr,socfpga-a10-fpga-mgr";
			reg = <0xffd03000 0x00001000>,
				<0xffcfe400 0x00000100>;
			reg-names = "axi_slave0", "axi_slave1";
			interrupt-parent = <&user_system_processor_hps_hps_arm_gic_0>;
			interrupts = <0 123 4>;
			transport = "mmio";	/* embeddedsw.dts.params.transport type STRING */
			clocks = <&l4_mp_clk>;	/* appended from boardinfo */
			resets = <&user_system_processor_hps_hps_i_rst_mgr_rstmgr 131>;	/* appended from boardinfo */
		}; //end fpgamgr@0xffd03000 (user_system_processor_hps_hps_i_fpga_mgr_fpgamgrregs)

		user_system_processor_hps_hps_timer: timer@0xffffc600 {
			compatible = "arm,cortex-a9-twd-timer-22.1", "arm,cortex-a9-twd-timer";
			reg = <0xffffc600 0x00000100>;
			interrupt-parent = <&user_system_processor_hps_hps_arm_gic_0>;
			interrupts = <1 13 3844>;
			clocks = <&mpu_periph_clk>;
		}; //end timer@0xffffc600 (user_system_processor_hps_hps_timer)

		user_system_processor_hps_hps_i_timer_sp_0_timer: timer@0xffc02700 {
			compatible = "snps,dw-apb-timer-sp-22.1", "snps,dw-apb-timer-sp";
			reg = <0xffc02700 0x00000100>;
			interrupt-parent = <&user_system_processor_hps_hps_arm_gic_0>;
			interrupts = <0 115 4>;
			clocks = <&l4_sp_clk>;
			clock-names = "timer";	/* embeddedsw.dts.params.clock-names type STRING */
		}; //end timer@0xffc02700 (user_system_processor_hps_hps_i_timer_sp_0_timer)

		user_system_processor_hps_hps_i_timer_sp_1_timer: timer@0xffc02800 {
			compatible = "snps,dw-apb-timer-sp-22.1", "snps,dw-apb-timer-sp";
			reg = <0xffc02800 0x00000100>;
			interrupt-parent = <&user_system_processor_hps_hps_arm_gic_0>;
			interrupts = <0 116 4>;
			clocks = <&l4_sp_clk>;
			clock-names = "timer";	/* embeddedsw.dts.params.clock-names type STRING */
		}; //end timer@0xffc02800 (user_system_processor_hps_hps_i_timer_sp_1_timer)

		user_system_processor_hps_hps_i_timer_sys_0_timer: timer@0xffd00000 {
			compatible = "snps,dw-apb-timer-osc-22.1", "snps,dw-apb-timer-osc";
			reg = <0xffd00000 0x00000100>;
			interrupt-parent = <&user_system_processor_hps_hps_arm_gic_0>;
			interrupts = <0 117 4>;
			clocks = <&l4_sys_free_clk>;
			clock-names = "timer";	/* embeddedsw.dts.params.clock-names type STRING */
			resets = <&user_system_processor_hps_hps_i_rst_mgr_rstmgr 66>;	/* appended from boardinfo */
		}; //end timer@0xffd00000 (user_system_processor_hps_hps_i_timer_sys_0_timer)

		user_system_processor_hps_hps_i_timer_sys_1_timer: timer@0xffd00100 {
			compatible = "snps,dw-apb-timer-osc-22.1", "snps,dw-apb-timer-osc";
			reg = <0xffd00100 0x00000100>;
			interrupt-parent = <&user_system_processor_hps_hps_arm_gic_0>;
			interrupts = <0 118 4>;
			clocks = <&l4_sys_free_clk>;
			clock-names = "timer";	/* embeddedsw.dts.params.clock-names type STRING */
			resets = <&user_system_processor_hps_hps_i_rst_mgr_rstmgr 67>;	/* appended from boardinfo */
		}; //end timer@0xffd00100 (user_system_processor_hps_hps_i_timer_sys_1_timer)

		user_system_processor_hps_hps_i_watchdog_0_l4wd: timer@0xffd00200 {
			compatible = "snps,dw-wdt-22.1", "snps,dw-wdt";
			reg = <0xffd00200 0x00000100>;
			interrupt-parent = <&user_system_processor_hps_hps_arm_gic_0>;
			interrupts = <0 119 4>;
			clocks = <&l4_sys_free_clk>;
			clock-names = "timer";	/* embeddedsw.dts.params.clock-names type STRING */
			status = "disabled";	/* appended from boardinfo */
			resets = <&user_system_processor_hps_hps_i_rst_mgr_rstmgr 64>;	/* appended from boardinfo */
		}; //end timer@0xffd00200 (user_system_processor_hps_hps_i_watchdog_0_l4wd)

		user_system_processor_hps_hps_i_watchdog_1_l4wd: timer@0xffd00300 {
			compatible = "snps,dw-wdt-22.1", "snps,dw-wdt";
			reg = <0xffd00300 0x00000100>;
			interrupt-parent = <&user_system_processor_hps_hps_arm_gic_0>;
			interrupts = <0 120 4>;
			clocks = <&l4_sys_free_clk>;
			clock-names = "timer";	/* embeddedsw.dts.params.clock-names type STRING */
			resets = <&user_system_processor_hps_hps_i_rst_mgr_rstmgr 65>;	/* appended from boardinfo */
		}; //end timer@0xffd00300 (user_system_processor_hps_hps_i_watchdog_1_l4wd)

		user_system_processor_hps_hps_i_gpio_0_gpio: gpio@0xffc02900 {
			compatible = "snps,dw-apb-gpio", "snps,dw-gpio-22.1", "snps,dw-gpio";
			reg = <0xffc02900 0x00000100>;
			interrupt-parent = <&user_system_processor_hps_hps_arm_gic_0>;
			interrupts = <0 112 4>;
			clocks = <&l4_mp_clk>;
			#gpio-cells = <2>;
			gpio-controller;
			#address-cells = <1>;
			#size-cells = <0>;

			user_system_processor_hps_hps_i_gpio_0_gpio_porta: gpio-controller@0 {
				compatible = "snps,dw-apb-gpio-port";
				gpio-controller;
				#gpio-cells = <2>;
				snps,nr-gpios = <24>;
				reg = <0>;
				interrupt-controller;
				#interrupt-cells = <2>;
				interrupts = <0 112 4>;
				interrupt-parent = <&user_system_processor_hps_hps_arm_gic_0>;
			}; //end gpio-controller@0 (user_system_processor_hps_hps_i_gpio_0_gpio_porta)
		}; //end gpio@0xffc02900 (user_system_processor_hps_hps_i_gpio_0_gpio)

		user_system_processor_hps_hps_i_gpio_1_gpio: gpio@0xffc02a00 {
			compatible = "snps,dw-apb-gpio", "snps,dw-gpio-22.1", "snps,dw-gpio";
			reg = <0xffc02a00 0x00000100>;
			interrupt-parent = <&user_system_processor_hps_hps_arm_gic_0>;
			interrupts = <0 113 4>;
			clocks = <&l4_mp_clk>;
			#gpio-cells = <2>;
			gpio-controller;
			#address-cells = <1>;
			#size-cells = <0>;

			user_system_processor_hps_hps_i_gpio_1_gpio_porta: gpio-controller@0 {
				compatible = "snps,dw-apb-gpio-port";
				gpio-controller;
				#gpio-cells = <2>;
				snps,nr-gpios = <24>;
				reg = <0>;
				interrupt-controller;
				#interrupt-cells = <2>;
				interrupts = <0 113 4>;
				interrupt-parent = <&user_system_processor_hps_hps_arm_gic_0>;
			}; //end gpio-controller@0 (user_system_processor_hps_hps_i_gpio_1_gpio_porta)
		}; //end gpio@0xffc02a00 (user_system_processor_hps_hps_i_gpio_1_gpio)

		user_system_processor_hps_hps_i_gpio_2_gpio: gpio@0xffc02b00 {
			compatible = "snps,dw-apb-gpio", "snps,dw-gpio-22.1", "snps,dw-gpio";
			reg = <0xffc02b00 0x00000100>;
			interrupt-parent = <&user_system_processor_hps_hps_arm_gic_0>;
			interrupts = <0 114 4>;
			clocks = <&l4_mp_clk>;
			#gpio-cells = <2>;
			gpio-controller;
			#address-cells = <1>;
			#size-cells = <0>;

			user_system_processor_hps_hps_i_gpio_2_gpio_porta: gpio-controller@0 {
				compatible = "snps,dw-apb-gpio-port";
				gpio-controller;
				#gpio-cells = <2>;
				snps,nr-gpios = <14>;
				reg = <0>;
				interrupt-controller;
				#interrupt-cells = <2>;
				interrupts = <0 114 4>;
				interrupt-parent = <&user_system_processor_hps_hps_arm_gic_0>;
			}; //end gpio-controller@0 (user_system_processor_hps_hps_i_gpio_2_gpio_porta)
		}; //end gpio@0xffc02b00 (user_system_processor_hps_hps_i_gpio_2_gpio)

		user_system_processor_hps_hps_i_uart_0_uart: serial@0xffc02000 {
			compatible = "snps,dw-apb-uart-22.1", "snps,dw-apb-uart";
			reg = <0xffc02000 0x00000100>;
			interrupt-parent = <&user_system_processor_hps_hps_arm_gic_0>;
			interrupts = <0 110 4>;
			clocks = <&l4_sp_clk>;
			reg-io-width = <4>;	/* embeddedsw.dts.params.reg-io-width type NUMBER */
			reg-shift = <2>;	/* embeddedsw.dts.params.reg-shift type NUMBER */
			status = "okay";	/* embeddedsw.dts.params.status type STRING */
			resets = <&user_system_processor_hps_hps_i_rst_mgr_rstmgr 80>;	/* appended from boardinfo */
		}; //end serial@0xffc02000 (user_system_processor_hps_hps_i_uart_0_uart)

		user_system_processor_hps_hps_i_uart_1_uart: serial@0xffc02100 {
			compatible = "snps,dw-apb-uart-22.1", "snps,dw-apb-uart";
			reg = <0xffc02100 0x00000100>;
			interrupt-parent = <&user_system_processor_hps_hps_arm_gic_0>;
			interrupts = <0 111 4>;
			clocks = <&l4_sp_clk>;
			reg-io-width = <4>;	/* embeddedsw.dts.params.reg-io-width type NUMBER */
			reg-shift = <2>;	/* embeddedsw.dts.params.reg-shift type NUMBER */
			status = "okay";	/* embeddedsw.dts.params.status type STRING */
			resets = <&user_system_processor_hps_hps_i_rst_mgr_rstmgr 81>;	/* appended from boardinfo */
		}; //end serial@0xffc02100 (user_system_processor_hps_hps_i_uart_1_uart)

		user_system_processor_hps_hps_i_emac_emac0: ethernet@0xff800000 {
			compatible = "synopsys,dwmac-22.1", "altr,socfpga-stmmac", "snps,dwmac-3.72a", "snps,dwmac";
			reg = <0xff800000 0x00002000>;
			interrupt-parent = <&user_system_processor_hps_hps_arm_gic_0>;
			interrupts = <0 92 4>;
			clocks = <&l4_mp_clk>;	/* appended from boardinfo */
			clock-names = "stmmaceth";	/* embeddedsw.dts.params.clock-names type STRING */
			interrupt-names = "macirq";	/* embeddedsw.dts.params.interrupt-names type STRING */
			rx-fifo-depth = <16384>;	/* embeddedsw.dts.params.rx-fifo-depth type NUMBER */
			snps,multicast-filter-bins = <256>;	/* embeddedsw.dts.params.snps,multicast-filter-bins type NUMBER */
			snps,perfect-filter-entries = <128>;	/* embeddedsw.dts.params.snps,perfect-filter-entries type NUMBER */
			status = "disabled";	/* embeddedsw.dts.params.status type STRING */
			tx-fifo-depth = <4096>;	/* embeddedsw.dts.params.tx-fifo-depth type NUMBER */
			address-bits = <48>;
			max-frame-size = <1518>;
			local-mac-address = [00 00 00 00 00 00];
			resets = <&user_system_processor_hps_hps_i_rst_mgr_rstmgr 32>;	/* appended from boardinfo */
			reset-names = "stmmaceth";	/* appended from boardinfo */
			altr,sysmgr-syscon = <&user_system_processor_hps_hps_i_sys_mgr_core 0x00000044 0>;	/* appended from boardinfo */
		}; //end ethernet@0xff800000 (user_system_processor_hps_hps_i_emac_emac0)

		user_system_processor_hps_hps_i_emac_emac1: ethernet@0xff802000 {
			compatible = "synopsys,dwmac-22.1", "altr,socfpga-stmmac", "snps,dwmac-3.72a", "snps,dwmac";
			reg = <0xff802000 0x00002000>;
			interrupt-parent = <&user_system_processor_hps_hps_arm_gic_0>;
			interrupts = <0 93 4>;
			clocks = <&l4_mp_clk>;	/* appended from boardinfo */
			clock-names = "stmmaceth";	/* embeddedsw.dts.params.clock-names type STRING */
			interrupt-names = "macirq";	/* embeddedsw.dts.params.interrupt-names type STRING */
			rx-fifo-depth = <16384>;	/* embeddedsw.dts.params.rx-fifo-depth type NUMBER */
			snps,multicast-filter-bins = <256>;	/* embeddedsw.dts.params.snps,multicast-filter-bins type NUMBER */
			snps,perfect-filter-entries = <128>;	/* embeddedsw.dts.params.snps,perfect-filter-entries type NUMBER */
			status = "disabled";	/* embeddedsw.dts.params.status type STRING */
			tx-fifo-depth = <4096>;	/* embeddedsw.dts.params.tx-fifo-depth type NUMBER */
			address-bits = <48>;
			max-frame-size = <3800>;	/* appended from boardinfo */
			local-mac-address = [00 00 00 00 00 00];
			resets = <&user_system_processor_hps_hps_i_rst_mgr_rstmgr 33>;	/* appended from boardinfo */
			reset-names = "stmmaceth";	/* appended from boardinfo */
			altr,sysmgr-syscon = <&user_system_processor_hps_hps_i_sys_mgr_core 0x00000048 0>;	/* appended from boardinfo */
			phy-mode = "rgmii";	/* appended from boardinfo */
			phy-addr = <0xffffffff>;	/* appended from boardinfo */
			txd0-skew-ps = <0>;	/* appended from boardinfo */
			txd1-skew-ps = <0>;	/* appended from boardinfo */
			txd2-skew-ps = <0>;	/* appended from boardinfo */
			txd3-skew-ps = <0>;	/* appended from boardinfo */
			rxd0-skew-ps = <420>;	/* appended from boardinfo */
			rxd1-skew-ps = <420>;	/* appended from boardinfo */
			rxd2-skew-ps = <420>;	/* appended from boardinfo */
			rxd3-skew-ps = <420>;	/* appended from boardinfo */
			txen-skew-ps = <0>;	/* appended from boardinfo */
			txc-skew-ps = <1860>;	/* appended from boardinfo */
			rxdv-skew-ps = <420>;	/* appended from boardinfo */
			rxc-skew-ps = <1680>;	/* appended from boardinfo */
		}; //end ethernet@0xff802000 (user_system_processor_hps_hps_i_emac_emac1)

		user_system_processor_hps_hps_i_emac_emac2: ethernet@0xff804000 {
			compatible = "synopsys,dwmac-22.1", "altr,socfpga-stmmac", "snps,dwmac-3.72a", "snps,dwmac";
			reg = <0xff804000 0x00002000>;
			interrupt-parent = <&user_system_processor_hps_hps_arm_gic_0>;
			interrupts = <0 94 4>;
			clocks = <&l4_mp_clk>;	/* appended from boardinfo */
			clock-names = "stmmaceth";	/* embeddedsw.dts.params.clock-names type STRING */
			interrupt-names = "macirq";	/* embeddedsw.dts.params.interrupt-names type STRING */
			rx-fifo-depth = <16384>;	/* embeddedsw.dts.params.rx-fifo-depth type NUMBER */
			snps,multicast-filter-bins = <256>;	/* embeddedsw.dts.params.snps,multicast-filter-bins type NUMBER */
			snps,perfect-filter-entries = <128>;	/* embeddedsw.dts.params.snps,perfect-filter-entries type NUMBER */
			status = "disabled";	/* embeddedsw.dts.params.status type STRING */
			tx-fifo-depth = <4096>;	/* embeddedsw.dts.params.tx-fifo-depth type NUMBER */
			address-bits = <48>;
			max-frame-size = <3800>;	/* appended from boardinfo */
			local-mac-address = [00 00 00 00 00 00];
			resets = <&user_system_processor_hps_hps_i_rst_mgr_rstmgr 34>;	/* appended from boardinfo */
			reset-names = "stmmaceth";	/* appended from boardinfo */
			altr,sysmgr-syscon = <&user_system_processor_hps_hps_i_sys_mgr_core 0x0000004c 0>;	/* appended from boardinfo */
			phy-mode = "rgmii";	/* appended from boardinfo */
			phy-addr = <0xffffffff>;	/* appended from boardinfo */
			txd0-skew-ps = <0>;	/* appended from boardinfo */
			txd1-skew-ps = <0>;	/* appended from boardinfo */
			txd2-skew-ps = <0>;	/* appended from boardinfo */
			txd3-skew-ps = <0>;	/* appended from boardinfo */
			rxd0-skew-ps = <420>;	/* appended from boardinfo */
			rxd1-skew-ps = <420>;	/* appended from boardinfo */
			rxd2-skew-ps = <420>;	/* appended from boardinfo */
			rxd3-skew-ps = <420>;	/* appended from boardinfo */
			txen-skew-ps = <0>;	/* appended from boardinfo */
			txc-skew-ps = <1860>;	/* appended from boardinfo */
			rxdv-skew-ps = <420>;	/* appended from boardinfo */
			rxc-skew-ps = <1680>;	/* appended from boardinfo */
		}; //end ethernet@0xff804000 (user_system_processor_hps_hps_i_emac_emac2)

		user_system_processor_hps_hps_i_spim_0_spim: spi@0xffda4000 {
			compatible = "snps,dw-spi-mmio-22.1", "snps,dw-spi-mmio", "snps,dw-apb-ssi";
			reg = <0xffda4000 0x00000100>;
			interrupt-parent = <&user_system_processor_hps_hps_arm_gic_0>;
			interrupts = <0 103 4>;
			clocks = <&spi_m_clk>;
			#address-cells = <1>;	/* embeddedsw.dts.params.#address-cells type NUMBER */
			#size-cells = <0>;	/* embeddedsw.dts.params.#size-cells type NUMBER */
			bus-num = <0>;	/* embeddedsw.dts.params.bus-num type NUMBER */
			num-chipselect = <4>;	/* embeddedsw.dts.params.num-chipselect type NUMBER */
			status = "okay";	/* embeddedsw.dts.params.status type STRING */
		}; //end spi@0xffda4000 (user_system_processor_hps_hps_i_spim_0_spim)

		user_system_processor_hps_hps_i_spim_1_spim: spi@0xffda5000 {
			compatible = "snps,dw-spi-mmio-22.1", "snps,dw-spi-mmio", "snps,dw-apb-ssi";
			reg = <0xffda5000 0x00000100>;
			interrupt-parent = <&user_system_processor_hps_hps_arm_gic_0>;
			interrupts = <0 104 4>;
			clocks = <&spi_m_clk>;
			#address-cells = <1>;	/* embeddedsw.dts.params.#address-cells type NUMBER */
			#size-cells = <0>;	/* embeddedsw.dts.params.#size-cells type NUMBER */
			bus-num = <0>;	/* embeddedsw.dts.params.bus-num type NUMBER */
			num-chipselect = <4>;	/* embeddedsw.dts.params.num-chipselect type NUMBER */
			status = "disabled";	/* embeddedsw.dts.params.status type STRING */
		}; //end spi@0xffda5000 (user_system_processor_hps_hps_i_spim_1_spim)

		user_system_processor_hps_hps_i_spis_0_spis: spi@0xffda2000 {
			compatible = "snps,dw-spi-mmio-22.1", "snps,dw-spi-mmio", "snps,dw-apb-ssi";
			reg = <0xffda2000 0x00000100>;
			interrupt-parent = <&user_system_processor_hps_hps_arm_gic_0>;
			interrupts = <0 101 4>;
			clocks = <&l4_mp_clk>;
			#address-cells = <1>;	/* embeddedsw.dts.params.#address-cells type NUMBER */
			#size-cells = <0>;	/* embeddedsw.dts.params.#size-cells type NUMBER */
			bus-num = <0>;	/* embeddedsw.dts.params.bus-num type NUMBER */
			num-chipselect = <4>;	/* embeddedsw.dts.params.num-chipselect type NUMBER */
			status = "disabled";	/* embeddedsw.dts.params.status type STRING */
		}; //end spi@0xffda2000 (user_system_processor_hps_hps_i_spis_0_spis)

		user_system_processor_hps_hps_i_spis_1_spis: spi@0xffda3000 {
			compatible = "snps,dw-spi-mmio-22.1", "snps,dw-spi-mmio", "snps,dw-apb-ssi";
			reg = <0xffda3000 0x00000100>;
			interrupt-parent = <&user_system_processor_hps_hps_arm_gic_0>;
			interrupts = <0 102 4>;
			clocks = <&l4_mp_clk>;
			#address-cells = <1>;	/* embeddedsw.dts.params.#address-cells type NUMBER */
			#size-cells = <0>;	/* embeddedsw.dts.params.#size-cells type NUMBER */
			bus-num = <0>;	/* embeddedsw.dts.params.bus-num type NUMBER */
			num-chipselect = <4>;	/* embeddedsw.dts.params.num-chipselect type NUMBER */
			status = "disabled";	/* embeddedsw.dts.params.status type STRING */
		}; //end spi@0xffda3000 (user_system_processor_hps_hps_i_spis_1_spis)

		user_system_processor_hps_hps_i_i2c_0_i2c: i2c@0xffc02200 {
			compatible = "snps,designware-i2c-22.1", "snps,designware-i2c";
			reg = <0xffc02200 0x00000100>;
			interrupt-parent = <&user_system_processor_hps_hps_arm_gic_0>;
			interrupts = <0 105 4>;
			clocks = <&l4_sp_clk>;
			emptyfifo_hold_master = <1>;	/* embeddedsw.dts.params.emptyfifo_hold_master type NUMBER */
			status = "okay";	/* embeddedsw.dts.params.status type STRING */
			speed-mode = <0>;	/* appended from boardinfo */
			clock-frequency = <100000>;	/* appended from boardinfo */
			i2c-sda-falling-time-ns = <6000>;	/* appended from boardinfo */
			i2c-scl-falling-time-ns = <6000>;	/* appended from boardinfo */
		}; //end i2c@0xffc02200 (user_system_processor_hps_hps_i_i2c_0_i2c)

		user_system_processor_hps_hps_i_i2c_1_i2c: i2c@0xffc02300 {
			compatible = "snps,designware-i2c-22.1", "snps,designware-i2c";
			reg = <0xffc02300 0x00000100>;
			interrupt-parent = <&user_system_processor_hps_hps_arm_gic_0>;
			interrupts = <0 106 4>;
			clocks = <&l4_sp_clk>;
			emptyfifo_hold_master = <1>;	/* embeddedsw.dts.params.emptyfifo_hold_master type NUMBER */
			status = "okay";	/* embeddedsw.dts.params.status type STRING */
		}; //end i2c@0xffc02300 (user_system_processor_hps_hps_i_i2c_1_i2c)

		user_system_processor_hps_hps_i_i2c_emac_0_i2c: i2c@0xffc02400 {
			compatible = "snps,designware-i2c-22.1", "snps,designware-i2c";
			reg = <0xffc02400 0x00000100>;
			interrupt-parent = <&user_system_processor_hps_hps_arm_gic_0>;
			interrupts = <0 107 4>;
			clocks = <&l4_sp_clk>;
			emptyfifo_hold_master = <1>;	/* embeddedsw.dts.params.emptyfifo_hold_master type NUMBER */
			status = "disabled";	/* embeddedsw.dts.params.status type STRING */
		}; //end i2c@0xffc02400 (user_system_processor_hps_hps_i_i2c_emac_0_i2c)

		user_system_processor_hps_hps_i_i2c_emac_1_i2c: i2c@0xffc02500 {
			compatible = "snps,designware-i2c-22.1", "snps,designware-i2c";
			reg = <0xffc02500 0x00000100>;
			interrupt-parent = <&user_system_processor_hps_hps_arm_gic_0>;
			interrupts = <0 108 4>;
			clocks = <&l4_sp_clk>;
			emptyfifo_hold_master = <1>;	/* embeddedsw.dts.params.emptyfifo_hold_master type NUMBER */
			status = "disabled";	/* embeddedsw.dts.params.status type STRING */
		}; //end i2c@0xffc02500 (user_system_processor_hps_hps_i_i2c_emac_1_i2c)

		user_system_processor_hps_hps_i_i2c_emac_2_i2c: i2c@0xffc02600 {
			compatible = "snps,designware-i2c-22.1", "snps,designware-i2c";
			reg = <0xffc02600 0x00000100>;
			interrupt-parent = <&user_system_processor_hps_hps_arm_gic_0>;
			interrupts = <0 109 4>;
			clocks = <&l4_sp_clk>;
			emptyfifo_hold_master = <1>;	/* embeddedsw.dts.params.emptyfifo_hold_master type NUMBER */
			status = "disabled";	/* embeddedsw.dts.params.status type STRING */
		}; //end i2c@0xffc02600 (user_system_processor_hps_hps_i_i2c_emac_2_i2c)

		user_system_processor_hps_hps_i_qspi_QSPIDATA: flash@0xff809000 {
			compatible = "cadence,qspi-22.1", "cadence,qspi", "cdns,qspi-nor";
			reg = <0xff809000 0x00000100>,
				<0xffa00000 0x00000100>;
			reg-names = "axi_slave0", "axi_slave1";
			interrupt-parent = <&user_system_processor_hps_hps_arm_gic_0>;
			interrupts = <0 100 4>;
			clocks = <&qspi_clk>;	/* appended from boardinfo */
			bus-num = <2>;	/* embeddedsw.dts.params.bus-num type NUMBER */
			fifo-depth = <128>;	/* embeddedsw.dts.params.fifo-depth type NUMBER */
			num-chipselect = <4>;	/* embeddedsw.dts.params.num-chipselect type NUMBER */
			status = "disabled";	/* embeddedsw.dts.params.status type STRING */
			bank-width = <2>;
			device-width = <1>;
		}; //end flash@0xff809000 (user_system_processor_hps_hps_i_qspi_QSPIDATA)

		user_system_processor_hps_hps_i_sdmmc_sdmmc: flash@0xff808000 {
			compatible = "snps,mmc-22.1", "altr,socfpga-dw-mshc";
			reg = <0xff808000 0x00001000>;
			interrupt-parent = <&user_system_processor_hps_hps_arm_gic_0>;
			interrupts = <0 98 4>;
			clocks = <&l4_mp_clk &sdmmc_clk>;
			clock-names = "biu", "ciu";
			fifo-depth = <1024>;	/* embeddedsw.dts.params.fifo-depth type NUMBER */
			num-slots = <1>;	/* embeddedsw.dts.params.num-slots type NUMBER */
			status = "okay";	/* embeddedsw.dts.params.status type STRING */
			bank-width = <2>;
			device-width = <1>;
			supports-highspeed;	/* appended from boardinfo */
			broken-cd;	/* appended from boardinfo */
			resets = <&user_system_processor_hps_hps_i_rst_mgr_rstmgr 39>;	/* appended from boardinfo */
			cap-sd-highspeed;	/* appended from boardinfo */
			cap-mmc-highspeed;	/* appended from boardinfo */
			altr,dw-mshc-ciu-div = <3>;	/* appended from boardinfo */
			altr,dw-mshc-sdr-timing = <0 3>;	/* appended from boardinfo */
			pwr-en = <0>;	/* appended from boardinfo */
			#address-cells = <1>;	/* appended from boardinfo */
			#size-cells = <0>;	/* appended from boardinfo */
			bus-width = <8>;	/* appended from boardinfo */

			slot0: slot@0 {
				reg = <0>;	/* appended from boardinfo */
				bus-width = <8>;	/* appended from boardinfo */
			}; //end slot@0 (slot0)
		}; //end flash@0xff808000 (user_system_processor_hps_hps_i_sdmmc_sdmmc)

		user_system_processor_hps_hps_i_nand_NANDDATA: flash@0xffb90000 {
			compatible = "denali,nand-22.1", "denali,denali-nand-dt";
			reg = <0xffb90000 0x00010000>,
				<0xffb80000 0x00010000>;
			reg-names = "nand_data", "denali_reg";	/* embeddedsw.dts.params.reg-names type STRING */
			interrupt-parent = <&user_system_processor_hps_hps_arm_gic_0>;
			interrupts = <0 99 4>;
			clocks = <&l4_mp_clk>;
			#address-cells = <1>;	/* embeddedsw.dts.params.#address-cells type NUMBER */
			#size-cells = <1>;	/* embeddedsw.dts.params.#size-cells type NUMBER */
			status = "disabled";	/* embeddedsw.dts.params.status type STRING */
			bank-width = <2>;
			device-width = <1>;
		}; //end flash@0xffb90000 (user_system_processor_hps_hps_i_nand_NANDDATA)

		user_system_processor_hps_hps_i_usbotg_0_globgrp: usb@0xffb00000 {
			compatible = "snps,dwc-otg-22.1", "snps,dwc-otg", "snps,dwc2";
			reg = <0xffb00000 0x00040000>;
			interrupt-parent = <&user_system_processor_hps_hps_arm_gic_0>;
			interrupts = <0 95 4>;
			clocks = <&usb_clk>;
			clock-names = "otg";	/* embeddedsw.dts.params.clock-names type STRING */
			dev-nperio-tx-fifo-size = <4096>;	/* embeddedsw.dts.params.dev-nperio-tx-fifo-size type NUMBER */
			dev-perio-tx-fifo-size = "<512 512 512 512 512 512 512 512 512 512 512 512 512 512 512>";	/* embeddedsw.dts.params.dev-perio-tx-fifo-size type STRING */
			dev-rx-fifo-size = <512>;	/* embeddedsw.dts.params.dev-rx-fifo-size type NUMBER */
			dev-tx-fifo-size = "<512 512 512 512 512 512 512 512 512 512 512 512 512 512 512>";	/* embeddedsw.dts.params.dev-tx-fifo-size type STRING */
			dma-mask = <268435455>;	/* embeddedsw.dts.params.dma-mask type NUMBER */
			enable-dynamic-fifo = <1>;	/* embeddedsw.dts.params.enable-dynamic-fifo type NUMBER */
			host-nperio-tx-fifo-size = <2560>;	/* embeddedsw.dts.params.host-nperio-tx-fifo-size type NUMBER */
			host-perio-tx-fifo-size = <2560>;	/* embeddedsw.dts.params.host-perio-tx-fifo-size type NUMBER */
			host-rx-fifo-size = <2560>;	/* embeddedsw.dts.params.host-rx-fifo-size type NUMBER */
			phy-names = "usb2-phy";	/* embeddedsw.dts.params.phy-names type STRING */
			status = "disabled";	/* embeddedsw.dts.params.status type STRING */
			ulpi-ddr = <0>;	/* embeddedsw.dts.params.ulpi-ddr type NUMBER */
			voltage-switch = <0>;	/* embeddedsw.dts.params.voltage-switch type NUMBER */
			phys = <&usbphy0>;	/* appended from boardinfo */
		}; //end usb@0xffb00000 (user_system_processor_hps_hps_i_usbotg_0_globgrp)

		user_system_processor_hps_hps_i_usbotg_1_globgrp: usb@0xffb40000 {
			compatible = "snps,dwc-otg-22.1", "snps,dwc-otg", "snps,dwc2";
			reg = <0xffb40000 0x00040000>;
			interrupt-parent = <&user_system_processor_hps_hps_arm_gic_0>;
			interrupts = <0 96 4>;
			clocks = <&usb_clk>;
			clock-names = "otg";	/* embeddedsw.dts.params.clock-names type STRING */
			dev-nperio-tx-fifo-size = <4096>;	/* embeddedsw.dts.params.dev-nperio-tx-fifo-size type NUMBER */
			dev-perio-tx-fifo-size = "<512 512 512 512 512 512 512 512 512 512 512 512 512 512 512>";	/* embeddedsw.dts.params.dev-perio-tx-fifo-size type STRING */
			dev-rx-fifo-size = <512>;	/* embeddedsw.dts.params.dev-rx-fifo-size type NUMBER */
			dev-tx-fifo-size = "<512 512 512 512 512 512 512 512 512 512 512 512 512 512 512>";	/* embeddedsw.dts.params.dev-tx-fifo-size type STRING */
			dma-mask = <268435455>;	/* embeddedsw.dts.params.dma-mask type NUMBER */
			enable-dynamic-fifo = <1>;	/* embeddedsw.dts.params.enable-dynamic-fifo type NUMBER */
			host-nperio-tx-fifo-size = <2560>;	/* embeddedsw.dts.params.host-nperio-tx-fifo-size type NUMBER */
			host-perio-tx-fifo-size = <2560>;	/* embeddedsw.dts.params.host-perio-tx-fifo-size type NUMBER */
			host-rx-fifo-size = <2560>;	/* embeddedsw.dts.params.host-rx-fifo-size type NUMBER */
			phy-names = "usb2-phy";	/* embeddedsw.dts.params.phy-names type STRING */
			status = "disabled";	/* embeddedsw.dts.params.status type STRING */
			ulpi-ddr = <0>;	/* embeddedsw.dts.params.ulpi-ddr type NUMBER */
			voltage-switch = <0>;	/* embeddedsw.dts.params.voltage-switch type NUMBER */
		}; //end usb@0xffb40000 (user_system_processor_hps_hps_i_usbotg_1_globgrp)

		user_system_processor_hps_hps_scu: scu@0xffffc000 {
			compatible = "arm,corex-a9-scu-22.1", "arm,cortex-a9-scu";
			reg = <0xffffc000 0x00000100>;
		}; //end scu@0xffffc000 (user_system_processor_hps_hps_scu)

		pmu: pmu0 {
			#address-cells = <1>;	/* appended from boardinfo */
			#size-cells = <1>;	/* appended from boardinfo */
			compatible = "arm,cortex-a9-pmu";	/* appended from boardinfo */
			interrupt-parent = <&user_system_processor_hps_hps_arm_gic_0>;	/* appended from boardinfo */
			interrupts = <0 176 4 0 177 4>;	/* appended from boardinfo */
			ranges;	/* appended from boardinfo */

			cti0: cti0@ff118000 {
				compatible = "arm,coresight-cti";	/* appended from boardinfo */
				reg = <0xff118000 0x00001000>;	/* appended from boardinfo */
			}; //end cti0@ff118000 (cti0)

			cti1: cti0@ff119000 {
				compatible = "arm,coresight-cti";	/* appended from boardinfo */
				reg = <0xff119000 0x00001000>;	/* appended from boardinfo */
			}; //end cti0@ff119000 (cti1)
		}; //end pmu0 (pmu)

		usbphy0: usbphy0 {
			#phy-cells = <0>;	/* appended from boardinfo */
			compatible = "usb-nop-xceiv";	/* appended from boardinfo */
		}; //end usbphy0 (usbphy0)
	}; //end sopc@0 (sopc0)

	chosen {
		bootargs = "earlyprintk";
		stdout-path = "serial0:115200n8";	/* appended from boardinfo */
	}; //end chosen
}; //end /
